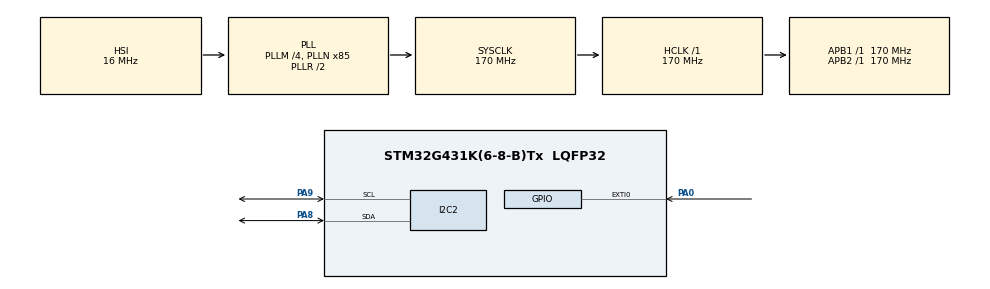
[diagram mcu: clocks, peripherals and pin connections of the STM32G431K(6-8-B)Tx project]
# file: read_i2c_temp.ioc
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ADC1.Channel-0\#ChannelRegularConversion=ADC_CHANNEL_TEMPSENSOR_ADC1
ADC1.ExternalTrigConv=ADC_EXTERNALTRIG_T15_TRGO
ADC1.NbrOfConversionFlag=1
ADC1.OffsetNumber-0\#ChannelRegularConversion=ADC_OFFSET_NONE
ADC1.Rank-0\#ChannelRegularConversion=1
ADC1.SamplingTime-0\#ChannelRegularConversion=ADC_SAMPLETIME_640CYCLES_5
ADC1.master=1
I2C2.CustomTiming=Enabled
I2C2.Timing=0x40B285C2
Mcu.Family=STM32G4
Mcu.Name=STM32G431K(6-8-B)Tx
Mcu.Package=LQFP32
NUCLEO-G431KB.Bsp_Common_DEMO=true
NUCLEO-G431KB.LD2=true
NUCLEO-G431KB.VCP=true
NVIC.ADC1_2_IRQn=true\:0\:0\:false\:false\:true\:true\:true\:true
NVIC.EXTI0_IRQn=true\:0\:0\:false\:true\:true\:1\:true\:true\:true
NVIC.I2C2_ER_IRQn=true\:0\:0\:false\:true\:true\:3\:true\:true\:true
NVIC.I2C2_EV_IRQn=true\:0\:0\:false\:true\:true\:2\:true\:true\:true
NVIC.PriorityGroup=NVIC_PRIORITYGROUP_4
PA0.GPIO_ModeDefaultEXTI=GPIO_MODE_IT_FALLING
PA0.Signal=GPXTI0
PA13.Mode=Serial_Wire
PA13.Signal=SYS_JTMS-SWDIO
PA14.Mode=Serial_Wire
PA14.Signal=SYS_JTCK-SWCLK
PA2.Signal=USART2_TX
PA3.Signal=USART2_RX
PA8.Mode=I2C
PA8.Signal=I2C2_SDA
PA9.Mode=I2C
PA9.Signal=I2C2_SCL
ProjectManager.HeapSize=0x200
ProjectManager.StackSize=0x400
ProjectManager.TargetToolchain=STM32CubeIDE
RCC.ADC12Freq_Value=170000000
RCC.AHBFreq_Value=170000000
RCC.APB1Freq_Value=170000000
RCC.APB1TimFreq_Value=170000000
RCC.APB2Freq_Value=170000000
RCC.APB2TimFreq_Value=170000000
RCC.CortexFreq_Value=170000000
RCC.EXTERNAL_CLOCK_VALUE=12288000
RCC.HCLKFreq_Value=170000000
RCC.HSE_VALUE=8000000
RCC.HSI48_VALUE=48000000
RCC.HSI_VALUE=16000000
RCC.LSE_VALUE=32768
RCC.PLLM=RCC_PLLM_DIV4
RCC.PLLN=85
RCC.SYSCLKFreq_VALUE=170000000
RCC.SYSCLKSource=RCC_SYSCLKSOURCE_PLLCLK
RCC.USBFreq_Value=170000000
RCC.VCOOutputFreq_Value=340000000
VP_ADC1_TempSens_Input.Mode=IN-TempSens
VP_ADC1_Vref_Input.Mode=IN-Vrefint
VP_NUCLEO-G431KB_VS_BSP_COMMON.Mode=COMMON
VP_RTC_VS_RTC_Activate.Mode=RTC_Enabled
VP_SYS_VS_DBSignals.Mode=DisableDeadBatterySignals
VP_SYS_V_PVD_IN.Mode=Mode_PVD_Int
VP_TIM15_VS_ClockSourceINT.Mode=Internal
board=NUCLEO-G431KB

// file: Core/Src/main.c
/* USER CODE BEGIN Header */
/**
  ******************************************************************************
  * @file           : main.c
  * @brief          : Main program body
  ******************************************************************************
  * @attention
  *
  * Copyright (c) 2026 STMicroelectronics.
  * All rights reserved.
  *
  * This software is licensed under terms that can be found in the LICENSE file
  * in the root directory of this software component.
  * If no LICENSE file comes with this software, it is provided AS-IS.
  *
  ******************************************************************************
  */
/* USER CODE END Header */
#include "main.h"
#include <stdio.h>
#include <string.h>

COM_InitTypeDef BspCOMInit;

ADC_HandleTypeDef hadc1;

I2C_HandleTypeDef hi2c2;

RTC_HandleTypeDef hrtc;

TIM_HandleTypeDef htim15;

/* USER CODE BEGIN PV */
// static const uint8_t HUM_ADDR = 0x45 << 1;
// static const uint8_t PRESS_ADDR = 0x19 << 1;
// static const uint8_t DISPLAY_ADDR = 0x3C << 1;
static const uint8_t TEMP_ADDR = 0x49 << 1;
static const uint8_t REG_TEMP = 0x00;
/* USER CODE END PV */

void SystemClock_Config(void);
static void MX_GPIO_Init(void);
static void MX_I2C2_Init(void);
static void MX_ADC1_Init(void);
static void MX_RTC_Init(void);
static void MX_TIM15_Init(void);
static void MX_NVIC_Init(void);

int main(void)
{

  /* USER CODE BEGIN 1 */
    HAL_StatusTypeDef ret = 0;
    HAL_StatusTypeDef retValue = 0;
	uint8_t buf[12];
	// save raw data
	int16_t val;
	float temp_c;
  /* USER CODE END 1 */

  /* MCU Configuration--------------------------------------------------------*/

  /* Reset of all peripherals, Initializes the Flash interface and the Systick. */
  HAL_Init();

  /* Configure the system clock */
  SystemClock_Config();

  /* Initialize all configured peripherals */
  MX_GPIO_Init();
  MX_I2C2_Init();
  MX_ADC1_Init();
  MX_RTC_Init();
  MX_TIM15_Init();

  /* Initialize interrupts */
  MX_NVIC_Init();

  /* Initialize leds */
  BSP_LED_Init(LED_GREEN);

  /* Initialize COM1 port (115200, 8 bits (7-bit data + 1 stop bit), no parity */
  BspCOMInit.BaudRate   = 115200;
  BspCOMInit.WordLength = COM_WORDLENGTH_8B;
  BspCOMInit.StopBits   = COM_STOPBITS_1;
  BspCOMInit.Parity     = COM_PARITY_NONE;
  BspCOMInit.HwFlowCtl  = COM_HWCONTROL_NONE;
  if (BSP_COM_Init(COM1, &BspCOMInit) != BSP_ERROR_NONE)
  {
    Error_Handler();
  }

  /* USER CODE BEGIN BSP */

  /* -- Sample board code to send message over COM1 port ---- */
  printf("Welcome to STM32 world !\n\r");

  /* -- Sample board code to switch on leds ---- */
  BSP_LED_On(LED_GREEN);

  /* USER CODE END BSP */

  /* Infinite loop */
  /* USER CODE BEGIN WHILE */

  //Find addresses
    printf("Scan slaves on i2c2:\r\n");
    uint8_t dummy = 0;

    for(int i=1; i<128; i++){
        retValue = HAL_I2C_Master_Transmit(&hi2c2, i<<1, &dummy, 0, 10);
        if(HAL_BUSY == retValue) printf("0x%02X - Busy\r\n", i);
        if(HAL_OK == retValue) printf("0x%02X - OK\r\n", i);
    }
//    uint8_t bufferI2c[10] = {0};

  while (1)
  {

/* -- Sample board code to toggle leds ---- */
       BSP_LED_Toggle(LED_GREEN);

    /* USER CODE END WHILE */

    /* USER CODE BEGIN 3 */
       // read temp logic
       buf[0] = REG_TEMP;
       // ack message
       ret = HAL_I2C_Master_Receive(&hi2c2, TEMP_ADDR, buf, 1, HAL_MAX_DELAY);
       if (ret != HAL_OK){
    	   strcpy((char*)buf, "Error Tx\r\n");
       } else {
    	   // read 2 bytes from the temp register
    	   ret = HAL_I2C_Master_Receive(&hi2c2, TEMP_ADDR, buf, 2, HAL_MAX_DELAY);
    	   if (ret != HAL_OK) {
    		   strcpy((char*)buf, "Error Rx\r\n");
    	   } else {
    		   // save raw data
    		   val = ((int16_t)buf[0] << 4) | buf[1] >> 4;
    		   // convert to 2's complement
    		   if (val > 0x7FF){
    			   val |= 0x7FF;
    		   }
    		   // concert temp to float value
    		   temp_c = val * 0.0625;
    		   // convert temp to decimal
    		   temp_c *= 100;

    	   }
       }
       printf("%u.%02u \r\n", (unsigned int)temp_c / 100, (unsigned int)temp_c % 100);
       HAL_Delay(1000);
  }
  /* USER CODE END 3 */
}

void SystemClock_Config(void)
{
  RCC_OscInitTypeDef RCC_OscInitStruct = {0};
  RCC_ClkInitTypeDef RCC_ClkInitStruct = {0};

  /** Configure the main internal regulator output voltage
  */
  HAL_PWREx_ControlVoltageScaling(PWR_REGULATOR_VOLTAGE_SCALE1_BOOST);

  /** Initializes the RCC Oscillators according to the specified parameters
  * in the RCC_OscInitTypeDef structure.
  */
  RCC_OscInitStruct.OscillatorType = RCC_OSCILLATORTYPE_HSI|RCC_OSCILLATORTYPE_LSI;
  RCC_OscInitStruct.HSIState = RCC_HSI_ON;
  RCC_OscInitStruct.HSICalibrationValue = RCC_HSICALIBRATION_DEFAULT;
  RCC_OscInitStruct.LSIState = RCC_LSI_ON;
  RCC_OscInitStruct.PLL.PLLState = RCC_PLL_ON;
  RCC_OscInitStruct.PLL.PLLSource = RCC_PLLSOURCE_HSI;
  RCC_OscInitStruct.PLL.PLLM = RCC_PLLM_DIV4;
  RCC_OscInitStruct.PLL.PLLN = 85;
  RCC_OscInitStruct.PLL.PLLP = RCC_PLLP_DIV2;
  RCC_OscInitStruct.PLL.PLLQ = RCC_PLLQ_DIV2;
  RCC_OscInitStruct.PLL.PLLR = RCC_PLLR_DIV2;
  if (HAL_RCC_OscConfig(&RCC_OscInitStruct) != HAL_OK)
  {
    Error_Handler();
  }

  /** Initializes the CPU, AHB and APB buses clocks
  */
  RCC_ClkInitStruct.ClockType = RCC_CLOCKTYPE_HCLK|RCC_CLOCKTYPE_SYSCLK
                              |RCC_CLOCKTYPE_PCLK1|RCC_CLOCKTYPE_PCLK2;
  RCC_ClkInitStruct.SYSCLKSource = RCC_SYSCLKSOURCE_PLLCLK;
  RCC_ClkInitStruct.AHBCLKDivider = RCC_SYSCLK_DIV1;
  RCC_ClkInitStruct.APB1CLKDivider = RCC_HCLK_DIV1;
  RCC_ClkInitStruct.APB2CLKDivider = RCC_HCLK_DIV1;

  if (HAL_RCC_ClockConfig(&RCC_ClkInitStruct, FLASH_LATENCY_4) != HAL_OK)
  {
    Error_Handler();
  }
}

/**
  * @brief NVIC Configuration.
  * @retval None
  */
static void MX_NVIC_Init(void)
{
  /* EXTI0_IRQn interrupt configuration */
  HAL_NVIC_SetPriority(EXTI0_IRQn, 0, 0);
  HAL_NVIC_EnableIRQ(EXTI0_IRQn);
  /* I2C2_EV_IRQn interrupt configuration */
  HAL_NVIC_SetPriority(I2C2_EV_IRQn, 0, 0);
  HAL_NVIC_EnableIRQ(I2C2_EV_IRQn);
  /* I2C2_ER_IRQn interrupt configuration */
  HAL_NVIC_SetPriority(I2C2_ER_IRQn, 0, 0);
  HAL_NVIC_EnableIRQ(I2C2_ER_IRQn);
}

static void MX_ADC1_Init(void)
{

  ADC_MultiModeTypeDef multimode = {0};
  ADC_ChannelConfTypeDef sConfig = {0};

  /** Common config
  */
  hadc1.Instance = ADC1;
  hadc1.Init.ClockPrescaler = ADC_CLOCK_SYNC_PCLK_DIV4;
  hadc1.Init.Resolution = ADC_RESOLUTION_12B;
  hadc1.Init.DataAlign = ADC_DATAALIGN_RIGHT;
  hadc1.Init.GainCompensation = 0;
  hadc1.Init.ScanConvMode = ADC_SCAN_DISABLE;
  hadc1.Init.EOCSelection = ADC_EOC_SINGLE_CONV;
  hadc1.Init.LowPowerAutoWait = DISABLE;
  hadc1.Init.ContinuousConvMode = DISABLE;
  hadc1.Init.NbrOfConversion = 1;
  hadc1.Init.DiscontinuousConvMode = DISABLE;
  hadc1.Init.ExternalTrigConv = ADC_EXTERNALTRIG_T15_TRGO;
  hadc1.Init.ExternalTrigConvEdge = ADC_EXTERNALTRIGCONVEDGE_RISING;
  hadc1.Init.DMAContinuousRequests = DISABLE;
  hadc1.Init.Overrun = ADC_OVR_DATA_PRESERVED;
  hadc1.Init.OversamplingMode = DISABLE;
  if (HAL_ADC_Init(&hadc1) != HAL_OK)
  {
    Error_Handler();
  }

  /** Configure the ADC multi-mode
  */
  multimode.Mode = ADC_MODE_INDEPENDENT;
  if (HAL_ADCEx_MultiModeConfigChannel(&hadc1, &multimode) != HAL_OK)
  {
    Error_Handler();
  }

  /** Configure Regular Channel
  */
  sConfig.Channel = ADC_CHANNEL_TEMPSENSOR_ADC1;
  sConfig.Rank = ADC_REGULAR_RANK_1;
  sConfig.SamplingTime = ADC_SAMPLETIME_640CYCLES_5;
  sConfig.SingleDiff = ADC_SINGLE_ENDED;
  sConfig.OffsetNumber = ADC_OFFSET_NONE;
  sConfig.Offset = 0;
  if (HAL_ADC_ConfigChannel(&hadc1, &sConfig) != HAL_OK)
  {
    Error_Handler();
  }

}

static void MX_I2C2_Init(void)
{

  hi2c2.Instance = I2C2;
  hi2c2.Init.Timing = 0x40B285C2;
  hi2c2.Init.OwnAddress1 = 0;
  hi2c2.Init.AddressingMode = I2C_ADDRESSINGMODE_7BIT;
  hi2c2.Init.DualAddressMode = I2C_DUALADDRESS_DISABLE;
  hi2c2.Init.OwnAddress2 = 0;
  hi2c2.Init.OwnAddress2Masks = I2C_OA2_NOMASK;
  hi2c2.Init.GeneralCallMode = I2C_GENERALCALL_DISABLE;
  hi2c2.Init.NoStretchMode = I2C_NOSTRETCH_DISABLE;
  if (HAL_I2C_Init(&hi2c2) != HAL_OK)
  {
    Error_Handler();
  }

  /** Configure Analogue filter
  */
  if (HAL_I2CEx_ConfigAnalogFilter(&hi2c2, I2C_ANALOGFILTER_ENABLE) != HAL_OK)
  {
    Error_Handler();
  }

  /** Configure Digital filter
  */
  if (HAL_I2CEx_ConfigDigitalFilter(&hi2c2, 0) != HAL_OK)
  {
    Error_Handler();
  }

}

static void MX_RTC_Init(void)
{

  /** Initialize RTC Only
  */
  hrtc.Instance = RTC;
  hrtc.Init.HourFormat = RTC_HOURFORMAT_24;
  hrtc.Init.AsynchPrediv = 127;
  hrtc.Init.SynchPrediv = 255;
  hrtc.Init.OutPut = RTC_OUTPUT_DISABLE;
  hrtc.Init.OutPutRemap = RTC_OUTPUT_REMAP_NONE;
  hrtc.Init.OutPutPolarity = RTC_OUTPUT_POLARITY_HIGH;
  hrtc.Init.OutPutType = RTC_OUTPUT_TYPE_OPENDRAIN;
  hrtc.Init.OutPutPullUp = RTC_OUTPUT_PULLUP_NONE;
  if (HAL_RTC_Init(&hrtc) != HAL_OK)
  {
    Error_Handler();
  }

}

static void MX_TIM15_Init(void)
{

  TIM_ClockConfigTypeDef sClockSourceConfig = {0};
  TIM_MasterConfigTypeDef sMasterConfig = {0};

  htim15.Instance = TIM15;
  htim15.Init.Prescaler = 0;
  htim15.Init.CounterMode = TIM_COUNTERMODE_UP;
  htim15.Init.Period = 65535;
  htim15.Init.ClockDivision = TIM_CLOCKDIVISION_DIV1;
  htim15.Init.RepetitionCounter = 0;
  htim15.Init.AutoReloadPreload = TIM_AUTORELOAD_PRELOAD_DISABLE;
  if (HAL_TIM_Base_Init(&htim15) != HAL_OK)
  {
    Error_Handler();
  }
  sClockSourceConfig.ClockSource = TIM_CLOCKSOURCE_INTERNAL;
  if (HAL_TIM_ConfigClockSource(&htim15, &sClockSourceConfig) != HAL_OK)
  {
    Error_Handler();
  }
  sMasterConfig.MasterOutputTrigger = TIM_TRGO_RESET;
  sMasterConfig.MasterSlaveMode = TIM_MASTERSLAVEMODE_DISABLE;
  if (HAL_TIMEx_MasterConfigSynchronization(&htim15, &sMasterConfig) != HAL_OK)
  {
    Error_Handler();
  }

}

static void MX_GPIO_Init(void)
{
  GPIO_InitTypeDef GPIO_InitStruct = {0};

  /* GPIO Ports Clock Enable */
  __HAL_RCC_GPIOF_CLK_ENABLE();
  __HAL_RCC_GPIOA_CLK_ENABLE();

  /*Configure GPIO pin : PA0 */
  GPIO_InitStruct.Pin = GPIO_PIN_0;
  GPIO_InitStruct.Mode = GPIO_MODE_IT_FALLING;
  GPIO_InitStruct.Pull = GPIO_NOPULL;
  HAL_GPIO_Init(GPIOA, &GPIO_InitStruct);

}

/* USER CODE BEGIN Header */
/**
  ******************************************************************************
  * @file           : main.c
  * @brief          : Main program body
  ******************************************************************************
  * @attention
  *
  * Copyright (c) 2026 STMicroelectronics.
  * All rights reserved.
  *
  * This software is licensed under terms that can be found in the LICENSE file
  * in the root directory of this software component.
  * If no LICENSE file comes with this software, it is provided AS-IS.
  *
  ******************************************************************************
  */
/* USER CODE END Header */

void Error_Handler(void)
{
  __disable_irq();
  while (1)
  {
  }
}
